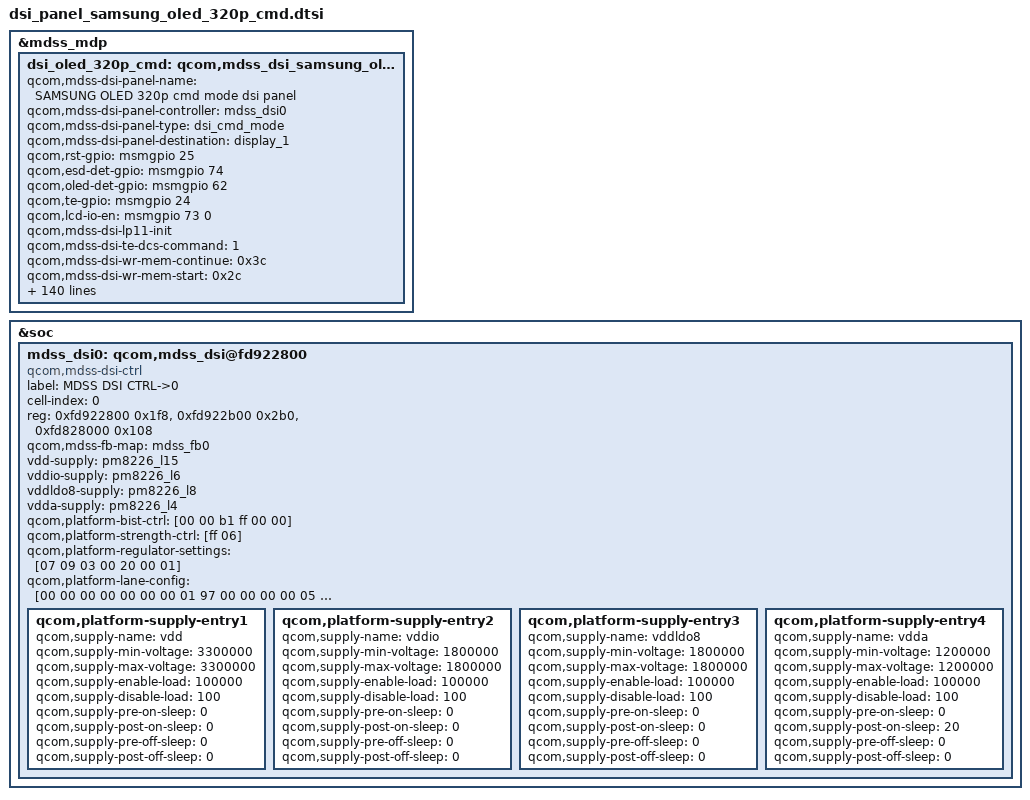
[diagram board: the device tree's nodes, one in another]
/* Copyright (c) 2012, Samsung Electronics Corporation. All rights reserved.
 *
 * This program is free software; you can redistribute it and/or modify
 * it under the terms of the GNU General Public License version 2 and
 * only version 2 as published by the Free Software Foundation.
 *
 * This program is distributed in the hope that it will be useful,
 * but WITHOUT ANY WARRANTY; without even the implied warranty of
 * MERCHANTABILITY or FITNESS FOR A PARTICULAR PURPOSE.  See the
 * GNU General Public License for more details.
 */

&mdss_mdp {
	dsi_oled_320p_cmd: qcom,mdss_dsi_samsung_oled_320p_cmd {
		qcom,mdss-dsi-panel-name = "SAMSUNG OLED 320p cmd mode dsi panel";
		qcom,mdss-dsi-panel-controller = <&mdss_dsi0>;
		qcom,mdss-dsi-panel-type = "dsi_cmd_mode";
		qcom,mdss-dsi-panel-destination = "display_1";
		qcom,rst-gpio = <&msmgpio 25 0>;
		qcom,esd-det-gpio = <&msmgpio 74 0>;
		qcom,oled-det-gpio = <&msmgpio 62 0>;
		qcom,te-gpio = <&msmgpio 24 0>;
		qcom,lcd-io-en = <&msmgpio 73 0>;
		qcom,mdss-dsi-lp11-init;
		qcom,mdss-dsi-te-dcs-command = <1>;
		qcom,mdss-dsi-wr-mem-continue = <0x3c>;
		qcom,mdss-dsi-wr-mem-start = <0x2c>;
		qcom,mdss-dsi-te-pin-select = <1>;
		qcom,mdss-dsi-te-check-enable;
		qcom,mdss-dsi-te-using-te-pin;
		qcom,mdss-dsi-panel-frame-rate = <60>;
		qcom,mdss-dsi-virtual-channel-id = <0>;
		qcom,mdss-dsi-stream = <0>;
		qcom,mdss-dsi-panel-width = <320>;
		qcom,mdss-dsi-panel-height = <320>;
		qcom,mdss-pan-physical-width-dimension = <29>;
		qcom,mdss-pan-physical-height-dimension = <29>;
		qcom,mdss-dsi-h-front-porch = <52>;
		qcom,mdss-dsi-h-back-porch = <4>;
		qcom,mdss-dsi-h-pulse-width = <4>;
		qcom,mdss-dsi-h-sync-skew = <0>;
		qcom,mdss-dsi-v-back-porch = <1>;
		qcom,mdss-dsi-v-front-porch = <500>;
		qcom,mdss-dsi-v-pulse-width = <1>;
		qcom,mdss-dsi-h-left-border = <0>;
		qcom,mdss-dsi-h-right-border = <0>;
		qcom,mdss-dsi-v-top-border = <0>;
		qcom,mdss-dsi-v-bottom-border = <0>;
		qcom,mdss-dsi-bpp = <24>;
		qcom,mdss-dsi-color-order = <0>;
		qcom,mdss-dsi-underflow-color = <0xff>;
		qcom,mdss-dsi-border-color = <0>;
		qcom,mdss-dsi-h-sync-pulse = <1>;
		qcom,mdss-dsi-traffic-mode = <2>;
		qcom,mdss-dsi-bllp-eof-power-mode;
		qcom,mdss-dsi-bllp-power-mode;
		qcom,mdss-dsi-lane-0-state;
		qcom,mdss-dsi-panel-timings = [83 1e 12 00 40 44 16 22 23 03 04 00];
		qcom,mdss-dsi-lane-map = <0>;
		qcom,mdss-dsi-t-clk-post = <0x04>;
		qcom,mdss-dsi-t-clk-pre = <0x1c>;
		qcom,mdss-dsi-bl-min-level = <0>;
		qcom,mdss-dsi-bl-max-level = <100>;
		qcom,mdss-dsi-dma-trigger = <4>;
		qcom,mdss-dsi-mdp-trigger = <0>;
		qcom,mdss-force-clk-lane-hs = <0>;
		qcom,mdss-dsi-tx-eot-append;
		qcom,mdss-dsi-bl-pmic-control-type = "bl_ctrl_dcs";
		qcom,mdss-dsi-panel-clock-rate = <449000000>;
		qcom,mdss-dsi-on-command = [
					39 01 00 00 01 00 03 F0 5A 5A
					39 01 00 00 00 00 03 F1 5A 5A
					39 01 00 00 00 00 03 F2 1C 28
					39 01 00 00 01 00 04 B5 00 01 00
					39 01 00 00 01 00 05 2A 00 14 01 53
					39 01 00 00 01 00 05 2B 00 00 01 3F
					39 01 00 00 01 00 0E F8 08 08 08 17 00 2A 02 26 00 00 02 00 00
					39 01 00 00 01 00 02 F7 02
					05 01 00 00 14 00 02 11 00      /* Sleep out */
					39 01 00 00 01 00 02 51 FF
					39 01 00 00 05 00 02 53 20
					39 01 00 00 01 00 02 55 00
					39 01 00 00 01 00 03 B1 00 09
					39 01 00 00 40 00 02 36 40
					39 01 00 00 01 00 03 F1 A5 A5
					05 01 00 00 01 00 02 29 00	/* Display On */
					];
		qcom,mdss-dsi-on-command-state = "dsi_lp_mode";
		qcom,mdss-dsi-bklt-command = [15 01 00 00 01 00 02 51 26
					15 01 00 00 01 00 02 51 13
					15 01 00 00 01 00 02 51 FF];
		qcom,mdss-dsi-bklt-command-state = "dsi_lp_mode";
		qcom,mdss-dsi-bklt-ctrl-command = [15 01 00 00 01 00 02 53 20];
		qcom,mdss-dsi-bklt-ctrl-command-state = "dsi_lp_mode";
		qcom,mdss-dsi-test-key-on-command = [39 01 00 00 00 00 03 F1 5A 5A];
		qcom,mdss-dsi-test-key-on-command-state = "dsi_lp_mode";
		qcom,mdss-dsi-test-key-off-command = [39 01 00 00 00 00 03 F1 A5 A5];
		qcom,mdss-dsi-test-key-off-command-state = "dsi_lp_mode";
		qcom,mdss-dsi-ldi-id-command = [06 01 00 00 00 00 01 D3];
		qcom,mdss-dsi-ldi-id-command-state = "dsi_lp_mode";
		qcom,mdss-dsi-ldi-mtp-command = [06 01 00 00 00 00 01 D4];
		qcom,mdss-dsi-ldi-mtp-command-state = "dsi_lp_mode";
		qcom,mdss-dsi-hbm-white-command = [15 01 00 00 01 00 02 51 EA];
		qcom,mdss-dsi-hbm-white-command-state = "dsi_lp_mode";
		qcom,mdss-dsi-pos-hbm-commands =
					"qcom,pos-hbm-elvss-cmd",
					"qcom,pos-def-elvss-cmd",
					"qcom,pos-default-cmd";
		qcom,pos-hbm-elvss-cmd = [39 01 00 00 01 00 03 B0 4C 00];
		qcom,pos-def-elvss-cmd = [39 01 00 00 01 00 03 B0 20 00];
		qcom,pos-default-cmd = [39 01 00 00 01 00 03 B0 00 00];
		qcom,mdss-dsi-pos-hbm-commands-state = "dsi_lp_mode";
		qcom,mdss-dsi-acl-on-command = [15 01 00 00 01 00 02 55 10];
		qcom,mdss-dsi-acl-on-command-state = "dsi_lp_mode";
		qcom,mdss-dsi-acl-off-command = [15 01 00 00 01 00 02 55 00];
		qcom,mdss-dsi-acl-off-command-state = "dsi_lp_mode";
		qcom,mdss-dsi-acl-sel-lock-command = [15 01 00 00 01 00 02 C0 13];
		qcom,mdss-dsi-acl-sel-lock-command-state = "dsi_lp_mode";
		qcom,mdss-dsi-acl-global-param-command = [15 01 00 00 01 00 02 B0 1B];
		qcom,mdss-dsi-acl-global-param-command-state = "dsi_lp_mode";
		qcom,mdss-dsi-acl-lut-enable-command = [15 01 00 00 01 00 02 D3 83];
		qcom,mdss-dsi-acl-lut-enable-command-state = "dsi_lp_mode";
		qcom,mdss-dsi-acl-table-command =
						"qcom,panel-acl-16-cmd",
						"qcom,panel-acl-21-cmd",
						"qcom,panel-acl-25-cmd";

		qcom,panel-acl-16-cmd = [39 01 00 00 01 00 42 C1 13 13 13 13
					13 13 13 13 13 13 13 13 13 13 13 13 13
					13 13 13 13 13 13 13 13 13 13 13 13 13
					13 13 13 13 13 13 13 13 14 15 16 17 18
					19 1A 1B 1C 1D 1E 1F 20 21 22 23 24 25
					26 27 28 29 2A 2B 2C 2D 2E];

		qcom,panel-acl-21-cmd = [39 01 00 00 01 00 42 C1 13 13 13 13 13
					13 13 13 13 13 13 13 13 13 13 13 13 13
					13 13 13 13 13 13 13 14 15 16 17 18 19
					1A 1B 1C 1D 1E 1F 20 21 22 23 24 25 26
					27 28 29 2A 2B 2C 2D 2E 2F 30 31 32 33
					34 35 36 37 38 39 3A 3B];

		qcom,panel-acl-25-cmd = [39 01 00 00 01 00 42 C1 13 13 13 13 13
					13 13 13 13 13 13 13 13 13 14 15 16 17
					18 19 1A 1B 1C 1D 1E 1F 20 21 22 23 24
					25 26 27 28 29 2A 2B 2C 2D 2E 2F 30 31
					32 33 34 35 36 37 38 39 3A 3B 3C 3D 3E
					3F 40 41 42 43 44 45 46];
		qcom,mdss-dsi-acl-table-command-state = "dsi_lp_mode";
		qcom,mdss-dsi-mode-commands =
					"qcom,panel-partial-mode-on-cmd",
					"qcom,panel-normal-mode-on-cmd",
					"qcom,panel-idle-mode-off-cmd",
					"qcom,panel-idle-mode-on-cmd";
		qcom,panel-partial-mode-on-cmd = [39 01 00 00 01 00 03 12 00 00];
		qcom,panel-normal-mode-on-cmd = [39 01 00 00 01 00 03 13 00 00];
		qcom,panel-idle-mode-off-cmd = [39 01 00 00 01 00 03 38 00 00];
		qcom,panel-idle-mode-on-cmd = [39 01 00 00 01 00 03 39 00 00];
		qcom,mdss-dsi-mode-commands-state = "dsi_lp_mode";
		qcom,mdss-dsi-partial-area-set-cmd = [39 01 00 00 01 00 03 30 00 00];
		qcom,mdss-dsi-partial-area-set-cmd-state = "dsi_lp_mode";
		qcom,mdss-dsi-off-command = [05 01 00 00 32 00 02 28 00
					05 01 00 00 78 00 02 10 00];
		qcom,mdss-dsi-off-command-state = "dsi_hs_mode";
		qcom,was-enable;
		qcom,partial-update-enabled;
		qcom,ulps-enabled;
	};
};
&soc {
	mdss_dsi0: qcom,mdss_dsi@fd922800 {
		compatible = "qcom,mdss-dsi-ctrl";
		label = "MDSS DSI CTRL->0";
		cell-index = <0>;
		reg = 	<0xfd922800 0x1f8>,
			<0xfd922b00 0x2b0>,
			<0xfd828000 0x108>;
		reg-names = "dsi_ctrl", "dsi_phy", "mmss_misc_phys";
		qcom,mdss-fb-map = <&mdss_fb0>;
		vdd-supply = <&pm8226_l15>;
		vddio-supply = <&pm8226_l6>;
		vddldo8-supply = <&pm8226_l8>;
		vdda-supply = <&pm8226_l4>;
		qcom,platform-bist-ctrl = [00 00 b1 ff 00 00];
		qcom,platform-strength-ctrl = [ff 06];
		qcom,platform-regulator-settings = [07 09 03 00 20 00 01];
		qcom,platform-lane-config = [00 00 00 00 00 00 00 01 97
			00 00 00 00 05 00 00 01 97
			00 00 00 00 0a 00 00 01 97
			00 00 00 00 0f 00 00 01 97
			00 c0 00 00 00 00 00 01 bb];
		qcom,platform-supply-entry1 {
			qcom,supply-name = "vdd";
			qcom,supply-min-voltage = <3300000>;
			qcom,supply-max-voltage = <3300000>;
			qcom,supply-enable-load = <100000>;
			qcom,supply-disable-load = <100>;
			qcom,supply-pre-on-sleep = <0>;
			qcom,supply-post-on-sleep = <0>;
			qcom,supply-pre-off-sleep = <0>;
			qcom,supply-post-off-sleep = <0>;
		};
		qcom,platform-supply-entry2 {
			qcom,supply-name = "vddio";
			qcom,supply-min-voltage = <1800000>;
			qcom,supply-max-voltage = <1800000>;
			qcom,supply-enable-load = <100000>;
			qcom,supply-disable-load = <100>;
			qcom,supply-pre-on-sleep = <0>;
			qcom,supply-post-on-sleep = <0>;
			qcom,supply-pre-off-sleep = <0>;
			qcom,supply-post-off-sleep = <0>;
		};
		qcom,platform-supply-entry3 {
			qcom,supply-name = "vddldo8";
			qcom,supply-min-voltage = <1800000>;
			qcom,supply-max-voltage = <1800000>;
			qcom,supply-enable-load = <100000>;
			qcom,supply-disable-load = <100>;
			qcom,supply-pre-on-sleep = <0>;
			qcom,supply-post-on-sleep = <0>;
			qcom,supply-pre-off-sleep = <0>;
			qcom,supply-post-off-sleep = <0>;
		};
		qcom,platform-supply-entry4 {
			qcom,supply-name = "vdda";
			qcom,supply-min-voltage = <1200000>;
			qcom,supply-max-voltage = <1200000>;
			qcom,supply-enable-load = <100000>;
			qcom,supply-disable-load = <100>;
			qcom,supply-pre-on-sleep = <0>;
			qcom,supply-post-on-sleep = <20>;
			qcom,supply-pre-off-sleep = <0>;
			qcom,supply-post-off-sleep = <0>;
		};
	};
};
